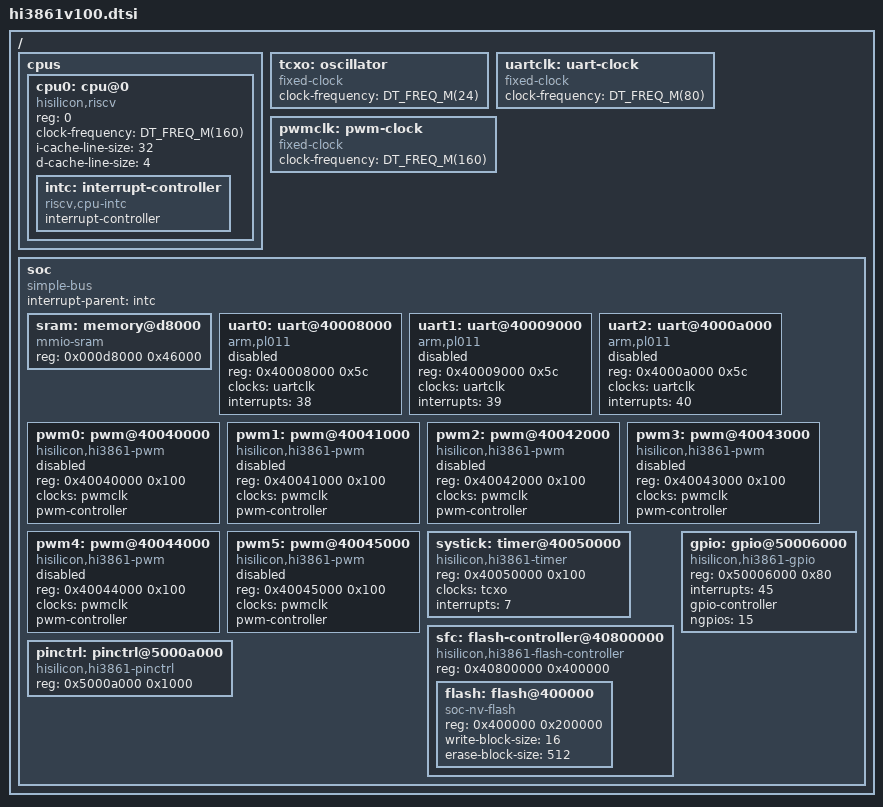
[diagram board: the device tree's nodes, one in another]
/*
 * Copyright (c) 2023 Chen Xingyu <hi@xingrz.me>
 * SPDX-License-Identifier: Apache-2.0
 */

#include <mem.h>
#include <freq.h>

/ {
	cpus {
		#address-cells = <1>;
		#size-cells = <0>;

		cpu0: cpu@0 {
			compatible = "hisilicon,riscv";
			reg = <0>;
			clock-frequency = <DT_FREQ_M(160)>;
			i-cache-line-size = <32>;
			d-cache-line-size = <4>;

			intc: interrupt-controller {
				compatible = "riscv,cpu-intc";
				interrupt-controller;
				#address-cells = <1>;
				#interrupt-cells = <1>;
			};
		};
	};

	tcxo: oscillator {
		compatible = "fixed-clock";
		clock-frequency = <DT_FREQ_M(24)>;
		#clock-cells = <0>;
	};

	uartclk: uart-clock {
		compatible = "fixed-clock";
		clock-frequency = <DT_FREQ_M(80)>;
		#clock-cells = <0>;
	};

	pwmclk: pwm-clock {
		compatible = "fixed-clock";
		clock-frequency = <DT_FREQ_M(160)>;
		#clock-cells = <0>;
	};

	soc {
		compatible = "simple-bus";
		interrupt-parent = <&intc>;
		#address-cells = <1>;
		#size-cells = <1>;
		ranges;

		sram: memory@d8000 {
			compatible = "mmio-sram";
			reg = <0x000d8000 0x46000>;
		};

		uart0: uart@40008000 {
			compatible = "arm,pl011";
			reg = <0x40008000 0x5c>;
			clocks = <&uartclk>;
			interrupts = <38>;
			status = "disabled";
		};

		uart1: uart@40009000 {
			compatible = "arm,pl011";
			reg = <0x40009000 0x5c>;
			clocks = <&uartclk>;
			interrupts = <39>;
			status = "disabled";
		};

		uart2: uart@4000a000 {
			compatible = "arm,pl011";
			reg = <0x4000a000 0x5c>;
			clocks = <&uartclk>;
			interrupts = <40>;
			status = "disabled";
		};

		pwm0: pwm@40040000 {
			compatible = "hisilicon,hi3861-pwm";
			reg = <0x40040000 0x100>;
			clocks = <&pwmclk>;
			pwm-controller;
			#pwm-cells = <2>;
			status = "disabled";
		};

		pwm1: pwm@40041000 {
			compatible = "hisilicon,hi3861-pwm";
			reg = <0x40041000 0x100>;
			clocks = <&pwmclk>;
			pwm-controller;
			#pwm-cells = <2>;
			status = "disabled";
		};

		pwm2: pwm@40042000 {
			compatible = "hisilicon,hi3861-pwm";
			reg = <0x40042000 0x100>;
			clocks = <&pwmclk>;
			pwm-controller;
			#pwm-cells = <2>;
			status = "disabled";
		};

		pwm3: pwm@40043000 {
			compatible = "hisilicon,hi3861-pwm";
			reg = <0x40043000 0x100>;
			clocks = <&pwmclk>;
			pwm-controller;
			#pwm-cells = <2>;
			status = "disabled";
		};

		pwm4: pwm@40044000 {
			compatible = "hisilicon,hi3861-pwm";
			reg = <0x40044000 0x100>;
			clocks = <&pwmclk>;
			pwm-controller;
			#pwm-cells = <2>;
			status = "disabled";
		};

		pwm5: pwm@40045000 {
			compatible = "hisilicon,hi3861-pwm";
			reg = <0x40045000 0x100>;
			clocks = <&pwmclk>;
			pwm-controller;
			#pwm-cells = <2>;
			status = "disabled";
		};

		systick: timer@40050000 {
			compatible = "hisilicon,hi3861-timer";
			reg = <0x40050000 0x100>;
			clocks = <&tcxo>;
			interrupts = <7>;
		};

		sfc: flash-controller@40800000 {
			compatible = "hisilicon,hi3861-flash-controller";
			reg = <0x40800000 0x400000>;

			#address-cells = <1>;
			#size-cells = <1>;

			flash: flash@400000 {
				compatible = "soc-nv-flash";
				reg = <0x400000 0x200000>;
				write-block-size = <16>;
				erase-block-size = <512>;
			};
		};

		gpio: gpio@50006000 {
			compatible = "hisilicon,hi3861-gpio";
			reg = <0x50006000 0x80>;
			interrupts = <45>;
			gpio-controller;
			#gpio-cells = <2>;
			ngpios = <15>;
		};

		pinctrl: pinctrl@5000a000 {
			compatible = "hisilicon,hi3861-pinctrl";
			reg = <0x5000a000 0x1000>;
		};
	};
};
